# R7FA2T107 register map
Vendor: Renesas Electronics Corporation; Series: RA2; File version: 1.00.00
CPU: CM23 r1p0, little endian, MPU, no FPU, VTOR, 2 interrupt priority bits, 32 interrupts
Registers are 8-bit, read-write, reset 0x0 unless marked. A register's access mark holds for its fields unless they carry their own. Offsets are from the block's base; [hi:lo] are bit positions; lines under a group give offsets from that group; {n}, {i} and the like mark numbered series; 'fields as' and 'values as' point back to an identical list; <NAME> marks a mode.

## ADC120 — 12-bit A/D Converter
Base 0x4005C000
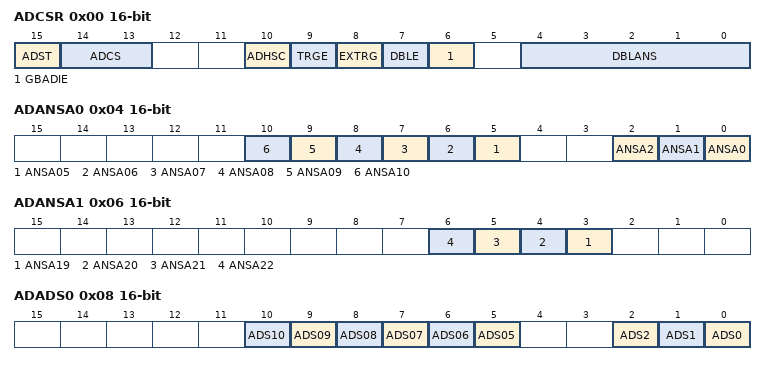
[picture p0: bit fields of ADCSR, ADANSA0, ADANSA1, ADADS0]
0x00 ADCSR 16-bit — A/D Control Register
  [15] ADST — A/D Conversion Start
    0=Stop A/D conversion process; 1=Start A/D conversion process
  [14:13] ADCS — Scan Mode Select
    0=Single scan mode; 1=Group scan mode; 2=Continuous scan mode; 3=Setting prohibited
  [10] ADHSC — A/D Conversion Mode Select
    0=High-speed A/D conversion mode; 1=Low-power A/D conversion mode
  [9] TRGE — Trigger Start Enable
    0=Disable A/D conversion to be started by the synchronous or asynchronous trigger; 1=Enable A/D conversion to be started by the synchronous or asynchronous trigger
  [8] EXTRG — Trigger Select
    0=Start A/D conversion by the synchronous trigger (ELC, GPT); 1=Start A/D conversion by the asynchronous trigger (ADTRG0)
  [7] DBLE — Double Trigger Mode Select
    0=Deselect double-trigger mode; 1=Select double-trigger mode
  [6] GBADIE — Group B Scan End Interrupt and ELC Event Enable
    0=Disable ADC120_GBADI interrupt generation on group B scan completion; 1=Enable ADC120_GBADI interrupt generation on group B scan completion
  [4:0] DBLANS — Double Trigger Channel Select
0x04 ADANSA0 16-bit — A/D Channel Select Register A0
  [all] fields
    0=Do not select associated input channel; 1=Select associated input channel
  [n] ANSA{n:02} (n=5..10) — A/D Conversion Channels Select
  [2] ANSA2 — A/D Conversion Channels Select
  [1] ANSA1 — A/D Conversion Channels Select
  [0] ANSA0 — A/D Conversion Channels Select
0x06 ADANSA1 16-bit — A/D Channel Select Register A1
  [all] fields
    values as the fields of ADANSA0
  [n-16] ANSA{n} (n=19..22) — A/D Conversion Channels Select
0x08 ADADS0 16-bit — A/D-Converted Value Addition/Average Channel Select Register 0
  [all] fields
    values as the fields of ADANSA0
  [n] ADS{n:02} (n=5..10) — A/D-Converted Value Addition/Average Channel Select
  [2] ADS2 — A/D-Converted Value Addition/Average Channel Select
  [1] ADS1 — A/D-Converted Value Addition/Average Channel Select
  [0] ADS0 — A/D-Converted Value Addition/Average Channel Select
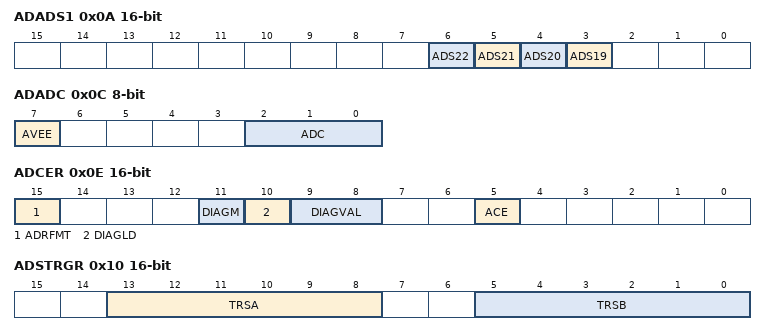
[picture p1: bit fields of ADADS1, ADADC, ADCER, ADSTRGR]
0x0A ADADS1 16-bit — A/D-Converted Value Addition/Average Channel Select Register 1
  [all] fields
    values as the fields of ADANSA0
  [n-16] ADS{n} (n=19..22) — A/D-Converted Value Addition/Average Channel Select
0x0C ADADC — A/D-Converted Value Addition/Average Count Select Register
  [7] AVEE — Average Mode Select
    0=Enable addition mode; 1=Enable average mode
  [2:0] ADC — Addition/Average Count Select
    0=1-time conversion (no addition, same as normal conversion); 1=2-time conversion (1 addition); 2=3-time conversion (2 additions); 3=4-time conversion (3 additions); 5=16-time conversion (15 additions); other=Others (Setting prohibited)
0x0E ADCER 16-bit — A/D Control Extended Register
  [15] ADRFMT — A/D Data Register Format Select
    0=Select right-justified for the A/D data register format; 1=Select left-justified for the A/D data register format
  [11] DIAGM — Self-Diagnosis Enable
    0=Disable ADC12 self-diagnosis; 1=Enable ADC12 self-diagnosis
  [10] DIAGLD — Self-Diagnosis Mode Select
    0=Select rotation mode for self-diagnosis voltage; 1=Select mixed mode for self-diagnosis voltage
  [9:8] DIAGVAL — Self-Diagnosis Conversion Voltage Select
    0=Setting prohibited when self-diagnosis is enabled; 1=0 volts; 2=Reference voltage × 1/2; 3=Reference voltage
  [5] ACE — A/D Data Register Automatic Clearing Enable
    0=Disable automatic clearing; 1=Enable automatic clearing
0x10 ADSTRGR 16-bit — A/D Conversion Start Trigger Select Register
  [13:8] TRSA — A/D Conversion Start Trigger Select
  [5:0] TRSB — A/D Conversion Start Trigger Select for Group B
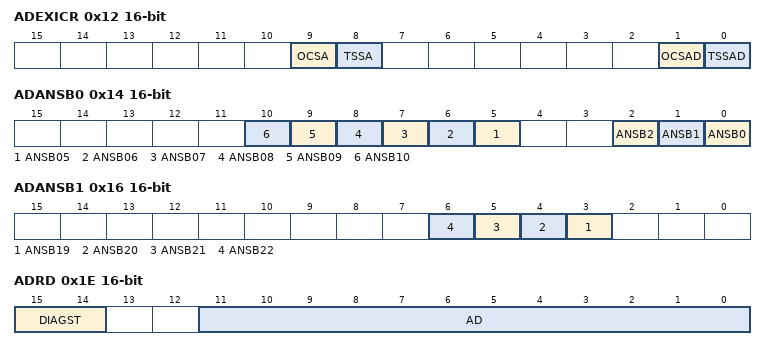
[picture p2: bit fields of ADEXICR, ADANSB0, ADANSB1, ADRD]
0x12 ADEXICR 16-bit — A/D Conversion Extended Input Control Register
  [9] OCSA — Internal Reference Voltage A/D Conversion Select
    0=Disable A/D conversion of internal reference voltage; 1=Enable A/D conversion of internal reference voltage
  [8] TSSA — Temperature Sensor Output A/D Conversion Select
    0=Disable A/D conversion of temperature sensor output; 1=Enable A/D conversion of temperature sensor output
  [1] OCSAD — Internal Reference Voltage A/D-Converted Value Addition/Average Mode Select
    0=Do not select addition/average mode for internal reference voltage; 1=Select addition/average mode for internal reference voltage
  [0] TSSAD — Temperature Sensor Output A/D-Converted Value Addition/Average Mode Select
    0=Do not select addition/average mode for temperature sensor output; 1=Select addition/average mode for temperature sensor output
0x14 ADANSB0 16-bit — A/D Channel Select Register B0
  [all] fields
    values as the fields of ADANSA0
  [n] ANSB{n:02} (n=5..10) — A/D Conversion Channels Select
  [2] ANSB2 — A/D Conversion Channels Select
  [1] ANSB1 — A/D Conversion Channels Select
  [0] ANSB0 — A/D Conversion Channels Select
0x16 ADANSB1 16-bit — A/D Channel Select Register B1
  [all] fields
    values as the fields of ADANSA0
  [n-16] ANSB{n} (n=19..22) — A/D Conversion Channels Select
0x18 ADDBLDR 16-bit ro — A/D Data Duplexing Register
  [15:0] ADDBLDR — Converted Value 15 to 0
0x1A ADTSDR 16-bit ro — A/D Temperature Sensor Data Register
  [15:0] ADTSDR — Converted Value 15 to 0
0x1C ADOCDR 16-bit ro — A/D Internal Reference Voltage Data Register
  [15:0] ADOCDR — Converted Value 15 to 0
0x1E ADRD 16-bit ro — A/D Self-Diagnosis Data Register
  [15:14] DIAGST — Self-Diagnosis Status
    0=Self-diagnosis not executed after power-on; 1=Self-diagnosis was executed using the 0 V voltage; 2=Self-diagnosis was executed using the reference voltage × 1/2; 3=Self-diagnosis was executed using the reference voltage 
  [11:0] AD — Converted Value 11 to 0
{0x20+2i} ADDR{i} (i=0..2) 16-bit ro — A/D Data Registers {i}
  [15:0] ADDR — Converted Value 15 to 0
{0x20+2i} ADDR{i} (i=5..10) 16-bit ro — A/D Data Registers {i}
  [15:0] ADDR — Converted Value 15 to 0
{0x20+2i} ADDR{i} (i=19..22) 16-bit ro — A/D Data Registers {i}
  [15:0] ADDR — Converted Value 15 to 0
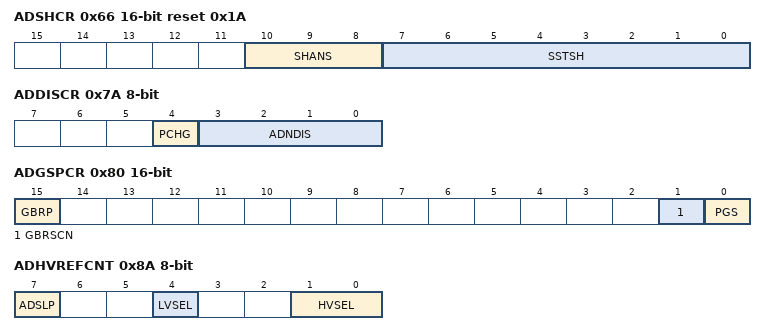
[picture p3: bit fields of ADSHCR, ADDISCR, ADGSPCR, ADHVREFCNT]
0x66 ADSHCR 16-bit reset 0x1A — A/D S&H Circuit Control Register
  [10:8] SHANS — Channel-Dedicated S&H Circuit Bypass Select
    0=Bypass the channel-dedicated S&H circuits; 1=Use the channel-dedicated S&H circuits
  [7:0] SSTSH — Channel-Dedicated S&H Circuit Sampling Time Setting
0x7A ADDISCR — A/D Disconnection Detection Control Register
  [4] PCHG — Precharge/discharge select
    0=Discharge; 1=Precharge
  [3:0] ADNDIS — Disconnection Detection Assist Setting
    0=The disconnection detection assist function is disabled; 1=Setting prohibited; other=Others (The number of states for the discharge or precharge period.)
0x7E ADACSR — A/D Conversion Operation Mode Select Register
  [1] ADSAC — Successive Approximation Control Setting
    0=Normal conversion mode (default); 1=Fast conversion mode
0x80 ADGSPCR 16-bit — A/D Group Scan Priority Control Register
  [15] GBRP — Single Scan Continuous Start
    0=Single scan is not continuously activated; 1=Single scan for the group with the lower-priority is continuously activated
  [1] GBRSCN — Lower-Priority Group Restart Setting
    0=Disable rescanning of the group that was stopped in group priority operation; 1=Enable rescanning of the group that was stopped in group priority operation
  [0] PGS — Group Priority Operation Setting
    0=Operate without group priority control; 1=Operate with group priority control
0x84 ADDBLDRA 16-bit ro — A/D Data Duplexing Register A
  [15:0] ADDBLDR — Converted Value 15 to 0
0x86 ADDBLDRB 16-bit ro — A/D Data Duplexing Register B
  [15:0] ADDBLDR — Converted Value 15 to 0
0x8A ADHVREFCNT — A/D High-Potential/Low-Potential Reference Voltage Control Register
  [7] ADSLP — Sleep
    0=Normal operation; 1=Standby state
  [4] LVSEL — Low-Potential Reference Voltage Select
    0=AVSS0 is selected as the low-potential reference voltage; 1=VREFL0 is selected as the low-potential reference voltage
  [1:0] HVSEL — High-Potential Reference Voltage Select
    0=AVCC0 is selected as the high-potential reference voltage; 1=VREFH0 is selected as the high-potential reference voltage; 2=Internal reference voltage is selected as the high-potential reference voltage; 3=No reference voltage pin is selected (internal node discharge)
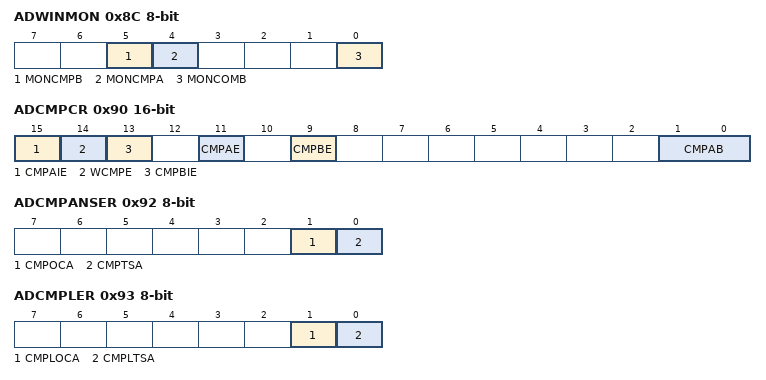
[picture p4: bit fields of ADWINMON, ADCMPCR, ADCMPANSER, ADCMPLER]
0x8C ADWINMON ro — A/D Compare Function Window A/B Status Monitor Register
  [5] MONCMPB — Comparison Result Monitor B
    0=Window B comparison conditions are not met; 1=Window B comparison conditions are met
  [4] MONCMPA — Comparison Result Monitor A
    0=Window A comparison conditions are not met; 1=Window A comparison conditions are met
  [0] MONCOMB — Combination Result Monitor
    0=Window A/B composite conditions are not met; 1=Window A/B composite conditions are met
0x90 ADCMPCR 16-bit — A/D Compare Function Control Register
  [15] CMPAIE — Compare A Interrupt Enable
    0=Disable ADC120_CMPAI interrupt when comparison conditions (window A) are met; 1=Enable ADC120_CMPAI interrupt when comparison conditions (window A) are met
  [14] WCMPE — Window Function Setting
    0=Disable window function Window A and window B operate as a comparator to compare the single value on the lower side with the A/D conversion result; 1=Enable window function Window A and window B operate as a comparator to compare the two values on the upper and lower sides with the A/D conversion result
  [13] CMPBIE — Compare B Interrupt Enable
    0=Disable ADC120_CMPBI interrupt when comparison conditions (window B) are met; 1=Enable ADC120_CMPBI interrupt when comparison conditions (window B) are met
  [11] CMPAE — Compare Window A Operation Enable
    0=Disable compare window A operation. Disable ADC120_WCMPM and ADC120_WCMPUM outputs.; 1=Enable compare window A operation
  [9] CMPBE — Compare Window B Operation Enable
    0=Disable compare window B operation. Disable ADC120_WCMPM and ADC120_WCMPUM outputs.; 1=Enable compare window B operation
  [1:0] CMPAB — Window A/B Composite Conditions Setting
    0=Output ADC120_WCMPM when window A OR window B comparison conditions are met. Otherwise, output ADC120_WCMPUM.; 1=Output ADC120_WCMPM when window A EXOR window B comparison conditions are met. Otherwise, output ADC120_WCMPUM.; 2=Output ADC120_WCMPM when window A AND window B comparison conditions are met. Otherwise, output ADC120_WCMPUM.; 3=Setting prohibited
0x92 ADCMPANSER — A/D Compare Function Window A Extended Input Select Register
  [1] CMPOCA — Internal Reference Voltage Compare Select
    0=Exclude the internal reference voltage from the compare Window A target range; 1=Include the internal reference voltage in the compare Window A target range
  [0] CMPTSA — Temperature Sensor Output Compare Select
    0=Exclude the temperature sensor output from the compare Window A target range; 1=Include the temperature sensor output in the compare Window A target range
0x93 ADCMPLER — A/D Compare Function Window A Extended Input Comparison Condition Setting Register
  [1] CMPLOCA — Compare Window A Internal Reference Voltage Comparison Condition Select
    0=When window function is disabled (ADCMPCR.WCMPE = 0) : ADCMPDR0 value > A/D-converted value When window function is enabled (ADCMPCR.WCMPE = 1): A/D-converted value < ADCMPDR0 value, or A/D-converted value > ADCMPDR1 value; 1=When window function is disabled (ADCMPCR.WCMPE = 0): ADCMPDR0 value < A/D-converted value When window function is enabled (ADCMPCR.WCMPE = 1): ADCMPDR0 value < A/D-converted value < ADCMPDR1 value
  [0] CMPLTSA — Compare Window A Temperature Sensor Output Comparison Condition Select
    0=When window function is disabled (ADCMPCR.WCMPE = 0) : ADCMPDR0 value > A/D-converted valueCompare Window A Temperature Sensor Output Comparison Condition Select When window function is enabled (ADCMPCR.WCMPE = 1) : Compare Window A Temperature Sensor Output Comparison ConditionA/D-converted value < ADCMPDR0 value, or A/D-converted value > ADCMPDR1 value; 1=When window function is disabled (ADCMPCR.WCMPE = 0) : ADCMPDR0 value < A/D-converted value When window function is enabled (ADCMPCR.WCMPE = 1) : ADCMPDR0 value < A/D-converted value < ADCMPDR1 value
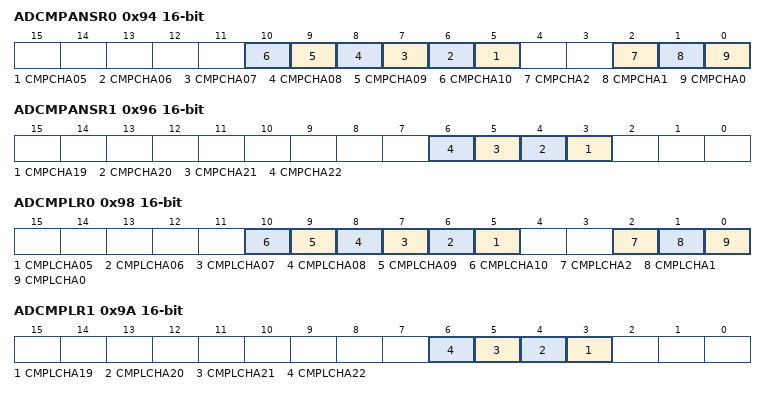
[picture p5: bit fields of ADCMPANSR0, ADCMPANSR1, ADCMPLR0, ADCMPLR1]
0x94 ADCMPANSR0 16-bit — A/D Compare Function Window A Channel Select Register 0
  [all] fields
    0=Disable compare function for associated input channel; 1=Enable compare function for associated input channel
  [n] CMPCHA{n:02} (n=5..10) — Compare Window A Channel Select
  [2] CMPCHA2 — Compare Window A Channel Select
  [1] CMPCHA1 — Compare Window A Channel Select
  [0] CMPCHA0 — Compare Window A Channel Select
0x96 ADCMPANSR1 16-bit — A/D Compare Function Window A Channel Select Register 1
  [all] fields
    values as the fields of ADCMPANSR0
  [n-16] CMPCHA{n} (n=19..22) — Compare Window A Channel Select
0x98 ADCMPLR0 16-bit — A/D Compare Function Window A Comparison Condition Setting Register 0
  [all] fields
    0=When window function is disabled (ADCMPCR.WCMPE = 0): ADCMPDR0 value > A/D-converted value When window function is enabled (ADCMPCR.WCMPE = 1): A/D-converted value < ADCMPDR0 value, or ADCMPDR1 value < A/D-converted value; 1=When window function is disabled (ADCMPCR.WCMPE = 0): ADCMPDR0 value < A/D-converted value When window function is enabled (ADCMPCR.WCMPE = 1): ADCMPDR0 value < A/D-converted value < ADCMPDR1 value
  [n] CMPLCHA{n:02} (n=5..10) — Compare Window A Comparison Condition Select
  [2] CMPLCHA2 — Compare Window A Comparison Condition Select
  [1] CMPLCHA1 — Compare Window A Comparison Condition Select
  [0] CMPLCHA0 — Compare Window A Comparison Condition Select
0x9A ADCMPLR1 16-bit — A/D Compare Function Window A Comparison Condition Setting Register 1
  [all] fields
    values as the fields of ADCMPLR0
  [n-16] CMPLCHA{n} (n=19..22) — Compare Window A Comparison Condition Select
{0x9C+2i} ADCMPDR{i} (i=0..1) 16-bit — A/D Compare Function Window A Lower-Side/Upper-Side Level Setting Register {i}
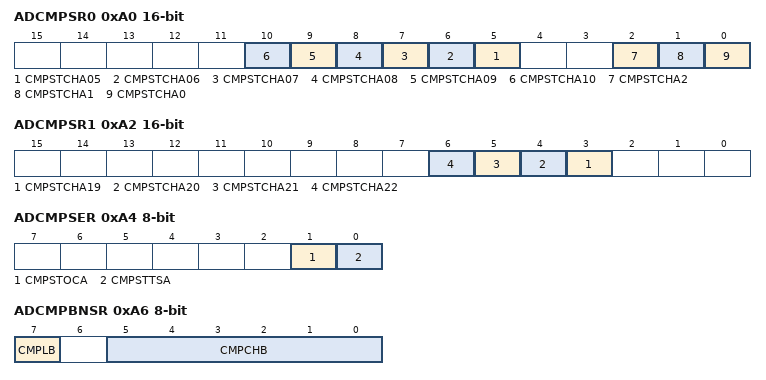
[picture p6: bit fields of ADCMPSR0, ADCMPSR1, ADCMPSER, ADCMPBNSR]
0xA0 ADCMPSR0 16-bit — A/D Compare Function Window A Channel Status Register 0
  [all] fields
    0=Comparison conditions are not met; 1=Comparison conditions are met
  [n] CMPSTCHA{n:02} (n=5..10) — Compare Window A Flag
  [2] CMPSTCHA2 — Compare Window A Flag
  [1] CMPSTCHA1 — Compare Window A Flag
  [0] CMPSTCHA0 — Compare Window A Flag
0xA2 ADCMPSR1 16-bit — A/D Compare Function Window A Channel Status Register 1
  [all] fields
    values as the fields of ADCMPSR0
  [n-16] CMPSTCHA{n} (n=19..22) — Compare Window A Flag
0xA4 ADCMPSER — A/D Compare Function Window A Extended Input Channel Status Register
  [1] CMPSTOCA — Compare Window A Internal Reference Voltage Compare Flag
    values as the fields of ADCMPSR0
  [0] CMPSTTSA — Compare Window A Temperature Sensor Output Compare Flag
    values as the fields of ADCMPSR0
0xA6 ADCMPBNSR — A/D Compare Function Window B Channel Select Register
  [7] CMPLB — Compare Window B Comparison Condition Setting
    0=When window function is disabled (ADCMPCR.WCMPE = 0): ADWINLLB value > A/D-converted value When window function is enabled (ADCMPCR.WCMPE = 1): A/D-converted value < ADWINLLB value, or ADWINULB value < A/D-converted value; 1=When window function is disabled (ADCMPCR.WCMPE = 0): ADWINLLB value < A/D-converted value When window function is enabled (ADCMPCR.WCMPE = 1): ADWINLLB value < A/D-converted value < ADWINULB value
  [5:0] CMPCHB — Compare Window B Channel Select
0xA8 ADWINLLB 16-bit — A/D Compare Function Window B Lower-Side/Upper-Side Level Setting Register L
0xAA ADWINULB 16-bit — A/D Compare Function Window B Lower-Side/Upper-Side Level Setting Register U
0xAC ADCMPBSR — A/D Compare Function Window B Status Register
  [0] CMPSTB — Compare Window B Flag
    values as the fields of ADCMPSR0
0xDD ADSSTRL reset 0xD — A/D Sampling State Register
  [7:0] SST — Sampling Time Setting
0xDE ADSSTRT reset 0xD — A/D Sampling State Register
  [7:0] SST — Sampling Time Setting
0xDF ADSSTRO reset 0xD — A/D Sampling State Register
  [7:0] SST — Sampling Time Setting
{0xE0+i} ADSSTR{i} (i=0..2) reset 0xD — A/D Sampling State Register {i}
  [7:0] SST — Sampling Time Setting
{0xE0+i} ADSSTR{i} (i=5..10) reset 0xD — A/D Sampling State Register {i}
  [7:0] SST — Sampling Time Setting
